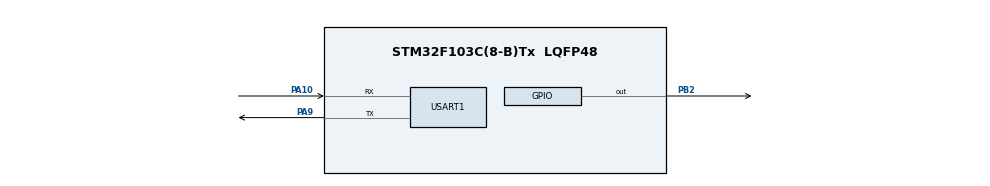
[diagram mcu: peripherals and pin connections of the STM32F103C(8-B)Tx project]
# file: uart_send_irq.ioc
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Mcu.Family=STM32F1
Mcu.Name=STM32F103C(8-B)Tx
Mcu.Package=LQFP48
NVIC.PriorityGroup=NVIC_PRIORITYGROUP_4
NVIC.USART1_IRQn=true\:1\:0\:true\:false\:true\:true\:true\:true
PA10.Mode=Asynchronous
PA10.Signal=USART1_RX
PA13.Mode=Serial_Wire
PA13.Signal=SYS_JTMS-SWDIO
PA14.Mode=Serial_Wire
PA14.Signal=SYS_JTCK-SWCLK
PA9.Mode=Asynchronous
PA9.Signal=USART1_TX
PB2.Signal=GPIO_Output
ProjectManager.HeapSize=0x3000
ProjectManager.StackSize=0x1000
ProjectManager.TargetToolchain=STM32CubeIDE
RCC.APB1Freq_Value=8000000
RCC.APB2Freq_Value=8000000
USART1.VirtualMode=VM_ASYNC
board=custom

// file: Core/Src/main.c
/* USER CODE BEGIN Header */
/**
Для организации передачи данных можно использовать прерывание «transmit data register empty».
 Оно вызывается каждый раз, когда регистр UART готов принять данные для передачи. Для его
  использования необходимо добавить/обновить код в трех файлах main.h, main.c, stm32f1xx_it.c

Передача данных по прерываниям в приведенной выше программе сводится к следующими шагам:
1. В основном потоке:
1) подготовить буфер с данными для передачи (функция output_
	buf_send_str):
	// copy buffer
	memcpy((void*) output_buf->buf, str, str_len);
	output_buf->start = 0;
	output_buf->end = str_len;
2) запустить прерывание:
	// enable interrupts
	__HAL_UART_ENABLE_IT(output_buf->huart, UART_IT_TXE);
	2. В обработчике прерывания (функции USART2_IRQHandler,
	output_buf_process_txe_it):
	1) проверить, что произошло прерывание «transmit data register
	empty». Это необходимо сделать, так как обработчик прерываний USART2_IRQHandler
	обслуживает все события, связанные с USART2:
	// ignore interruption if it isn’t related with data transmission
	if (!__HAL_UART_GET_FLAG(output_buf->huart, UART_
		FLAG_TXE)) {
		return 0;
	}
2) если данных для передачи нет, необходимо выключить прерывание, иначе перейти к следующему шагу:
	if (output_buf->start == output_buf->end) {
		// all data has been transmitted. Stop interruptions
		__HAL_UART_DISABLE_IT(output_buf->huart, UART_IT_
		TXE);
		return 0;
	}
3) перенести очередной байт из буфера в регистр UART для передачи данных:
	// move data from buffer to register
	output_buf->huart->Instance->TDR
	>buf[output_buf->start];
	output_buf->start++;

 */
/**
  ******************************************************************************
  * @file           : main.c
  * @brief          : Main program body
  ******************************************************************************
  * @attention
  *
  * Copyright (c) 2025 STMicroelectronics.
  * All rights reserved.
  *
  * This software is licensed under terms that can be found in the LICENSE file
  * in the root directory of this software component.
  * If no LICENSE file comes with this software, it is provided AS-IS.
  *
  ******************************************************************************
  */
/* USER CODE END Header */
#include "main.h"

/* USER CODE BEGIN Includes */
#include <stdio.h>
#include <string.h>

/* USER CODE END Includes */

UART_HandleTypeDef huart1;

void SystemClock_Config(void);
static void MX_GPIO_Init(void);
static void MX_USART1_UART_Init(void);

/* USER CODE BEGIN 0 */
// define global variable
output_buf_t project_output_buf;
/**
* Initialize output_buf_t object.
*/
int output_buf_init(output_buf_t *output_buf, UART_HandleTypeDef *huart)
{
	output_buf->start = 0;
	output_buf->end = 0;
	output_buf->huart = huart;
	return 0;
}

/**
* Send data to UART;
*/
int output_buf_send_str(output_buf_t *output_buf, const char *str) {
	if (output_buf->start != output_buf->end) {
		// Error: previous transmission isn't completed
		return -1;
	}
	size_t str_len = strlen(str);
	if (str_len > sizeof(output_buf->buf)) {
		// Error: str is too long for internal buffer
		return -2;
	}
	// copy buffer
	memcpy((void*) output_buf->buf, str, str_len);
	output_buf->start = 0;
	output_buf->end = str_len;
	// enable interrupts
	__HAL_UART_ENABLE_IT(output_buf->huart, UART_IT_TXE);
	return 0;
}

/**
* Process UART interruption.
*/
int output_buf_process_txe_it(output_buf_t *output_buf) {
	// ignore interruption if it isn't related with data transmission
	if (!__HAL_UART_GET_FLAG(output_buf->huart, UART_FLAG_TXE)) {
		return 0;
	}
	if (output_buf->start == output_buf->end) {
		// all data has been transmitted. Stop interruptions
		__HAL_UART_DISABLE_IT(output_buf->huart, UART_IT_TXE);
		return 0;
	}
	// move data from buffer to register
	output_buf->huart->Instance->DR = output_buf->buf[output_buf->start];
	output_buf->start++;
	return 0;
}
/* USER CODE END 0 */

int main(void)
{

  /* MCU Configuration--------------------------------------------------------*/

  /* Reset of all peripherals, Initializes the Flash interface and the Systick. */
  HAL_Init();

  /* Configure the system clock */
  SystemClock_Config();

  /* Initialize all configured peripherals */
  MX_GPIO_Init();
  MX_USART1_UART_Init();
  /* USER CODE BEGIN 2 */
  output_buf_init(&project_output_buf, &huart1);
  char buf[128];
  int current_time;
  /* USER CODE END 2 */

  /* Infinite loop */
  /* USER CODE BEGIN WHILE */
  while (1)
  {
	  current_time = HAL_GetTick();
	  sprintf(buf, "Time: %i\n", current_time);
	  output_buf_send_str(&project_output_buf, buf);
	  HAL_GPIO_TogglePin(GPIOB, GPIO_PIN_2);
	  HAL_Delay(500);
    /* USER CODE END WHILE */

  }
}

void SystemClock_Config(void)
{
  RCC_OscInitTypeDef RCC_OscInitStruct = {0};
  RCC_ClkInitTypeDef RCC_ClkInitStruct = {0};

  /** Initializes the RCC Oscillators according to the specified parameters
  * in the RCC_OscInitTypeDef structure.
  */
  RCC_OscInitStruct.OscillatorType = RCC_OSCILLATORTYPE_HSI;
  RCC_OscInitStruct.HSIState = RCC_HSI_ON;
  RCC_OscInitStruct.HSICalibrationValue = RCC_HSICALIBRATION_DEFAULT;
  RCC_OscInitStruct.PLL.PLLState = RCC_PLL_NONE;
  if (HAL_RCC_OscConfig(&RCC_OscInitStruct) != HAL_OK)
  {
    Error_Handler();
  }

  /** Initializes the CPU, AHB and APB buses clocks
  */
  RCC_ClkInitStruct.ClockType = RCC_CLOCKTYPE_HCLK|RCC_CLOCKTYPE_SYSCLK
                              |RCC_CLOCKTYPE_PCLK1|RCC_CLOCKTYPE_PCLK2;
  RCC_ClkInitStruct.SYSCLKSource = RCC_SYSCLKSOURCE_HSI;
  RCC_ClkInitStruct.AHBCLKDivider = RCC_SYSCLK_DIV1;
  RCC_ClkInitStruct.APB1CLKDivider = RCC_HCLK_DIV1;
  RCC_ClkInitStruct.APB2CLKDivider = RCC_HCLK_DIV1;

  if (HAL_RCC_ClockConfig(&RCC_ClkInitStruct, FLASH_LATENCY_0) != HAL_OK)
  {
    Error_Handler();
  }
}

static void MX_USART1_UART_Init(void)
{

  huart1.Instance = USART1;
  huart1.Init.BaudRate = 115200;
  huart1.Init.WordLength = UART_WORDLENGTH_8B;
  huart1.Init.StopBits = UART_STOPBITS_1;
  huart1.Init.Parity = UART_PARITY_NONE;
  huart1.Init.Mode = UART_MODE_TX_RX;
  huart1.Init.HwFlowCtl = UART_HWCONTROL_NONE;
  huart1.Init.OverSampling = UART_OVERSAMPLING_16;
  if (HAL_UART_Init(&huart1) != HAL_OK)
  {
    Error_Handler();
  }

}

static void MX_GPIO_Init(void)
{
  GPIO_InitTypeDef GPIO_InitStruct = {0};

  /* GPIO Ports Clock Enable */
  __HAL_RCC_GPIOB_CLK_ENABLE();
  __HAL_RCC_GPIOA_CLK_ENABLE();

  /*Configure GPIO pin Output Level */
  HAL_GPIO_WritePin(GPIOB, GPIO_PIN_2, GPIO_PIN_RESET);

  /*Configure GPIO pin : PB2 */
  GPIO_InitStruct.Pin = GPIO_PIN_2;
  GPIO_InitStruct.Mode = GPIO_MODE_OUTPUT_PP;
  GPIO_InitStruct.Pull = GPIO_NOPULL;
  GPIO_InitStruct.Speed = GPIO_SPEED_FREQ_LOW;
  HAL_GPIO_Init(GPIOB, &GPIO_InitStruct);

}

void Error_Handler(void)
{
  __disable_irq();
  while (1)
  {
  }
}
